# ATSAML21J18BU register map
Vendor: Microchip Technology Inc.; Series: SAML21; File version: B
CPU: CM0+ r0p1, little endian, no MPU, no FPU, VTOR, 2 interrupt priority bits, 29 interrupts
Registers are 32-bit, read-write, reset 0x0 unless marked. A register's access mark holds for its fields unless they carry their own. Offsets are from the block's base; [hi:lo] are bit positions; {n}, {i} and the like mark numbered series; 'fields as' and 'values as' point back to an identical list.

## MTB — Cortex-M0+ Micro-Trace Buffer
Base 0x41006000; register names take the prefix MTB_
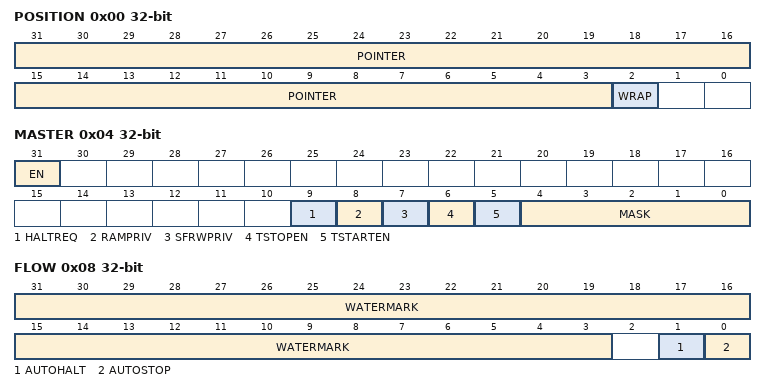
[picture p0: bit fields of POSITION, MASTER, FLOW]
0x00 POSITION — MTB Position
  [31:3] POINTER — Trace Packet Location Pointer
  [2] WRAP — Pointer Value Wraps
0x04 MASTER — MTB Master
  [31] EN — Main Trace Enable
  [9] HALTREQ — Halt Request
  [8] RAMPRIV — SRAM Privilege
  [7] SFRWPRIV — Special Function Register Write Privilege
  [6] TSTOPEN — Trace Stop Input Enable
  [5] TSTARTEN — Trace Start Input Enable
  [4:0] MASK — Maximum Value of the Trace Buffer in SRAM
0x08 FLOW — MTB Flow
  [31:3] WATERMARK — Watermark value
  [1] AUTOHALT — Auto Halt Request
  [0] AUTOSTOP — Auto Stop Tracing
0x0C BASE ro — MTB Base
0xF00 ITCTRL — MTB Integration Mode Control
0xFA0 CLAIMSET — MTB Claim Set
0xFA4 CLAIMCLR — MTB Claim Clear
0xFB0 LOCKACCESS — MTB Lock Access
0xFB4 LOCKSTATUS ro — MTB Lock Status
0xFB8 AUTHSTATUS ro — MTB Authentication Status
0xFBC DEVARCH ro — MTB Device Architecture
0xFC8 DEVID ro — MTB Device Configuration
0xFCC DEVTYPE ro — MTB Device Type
{0xFC0+4i} PID{i} ro (i=4..7) — Peripheral Identification {i}
{0xFE0+4i} PID{i} ro (i=0..3) — Peripheral Identification {i}
{0xFF0+4i} CID{i} ro (i=0..3) — Component Identification {i}

## OPAMP — Operational Amplifier
Base 0x43001800; register names take the prefix OPAMP_
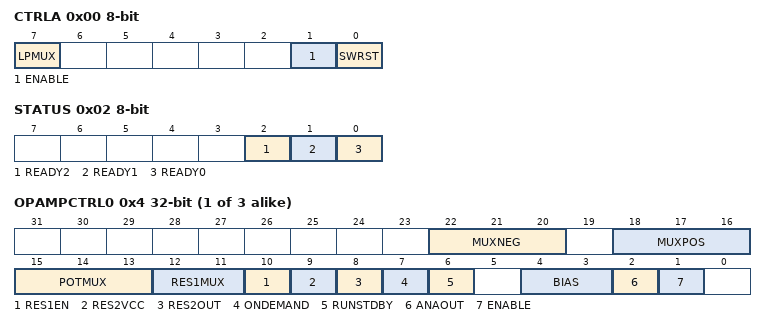
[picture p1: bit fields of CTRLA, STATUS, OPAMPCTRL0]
0x00 CTRLA 8-bit — Control A
  [7] LPMUX — Low-Power Mux
  [1] ENABLE
  [0] SWRST — Software Reset
0x02 STATUS 8-bit ro
  [2] READY2 — OPAMP 2 Ready
  [1] READY1 — OPAMP 1 Ready
  [0] READY0 — OPAMP 0 Ready
{0x4+4i} OPAMPCTRL{i} (i=0..2) — OPAMP n Control
  [22:20] MUXNEG — Negative Input Mux Selection
  [18:16] MUXPOS — Positive Input Mux Selection
  [15:13] POTMUX — Potentiometer Selection
  [12:11] RES1MUX — Resistor 1 Mux
  [10] RES1EN — Resistor 1 Enable
  [9] RES2VCC — Resistor ladder To VCC
  [8] RES2OUT — Resistor ladder To Output
  [7] ONDEMAND — On Demand Control
  [6] RUNSTDBY — Run in Standby
  [4:3] BIAS — Bias Selection
  [2] ANAOUT — Analog Output
  [1] ENABLE — Operational Amplifier Enable

## OSC32KCTRL — 32k Oscillators Control
Base 0x40001000; register names take the prefix OSC32KCTRL_
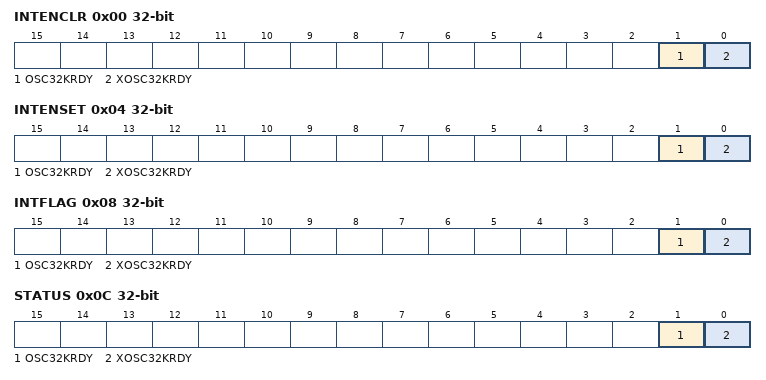
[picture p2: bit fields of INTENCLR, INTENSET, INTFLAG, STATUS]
0x00 INTENCLR — Interrupt Enable Clear
  [1] OSC32KRDY — OSC32K Ready Interrupt Enable
  [0] XOSC32KRDY — XOSC32K Ready Interrupt Enable
0x04 INTENSET — Interrupt Enable Set
  fields as INTENCLR
0x08 INTFLAG — Interrupt Flag Status and Clear
  [1] OSC32KRDY — OSC32K Ready
  [0] XOSC32KRDY — XOSC32K Ready
0x0C STATUS ro — Power and Clocks Status
  [1] OSC32KRDY — OSC32K Ready
  [0] XOSC32KRDY — XOSC32K Ready
0x10 RTCCTRL — Clock selection
  [2:0] RTCSEL — RTC Clock Selection
    0=ULP1K (1.024kHz from 32kHz internal ULP oscillator); 1=ULP32K (32.768kHz from 32kHz internal ULP oscillator); 2=OSC1K (1.024kHz from 32.768kHz internal oscillator); 3=OSC32K (32.768kHz from 32.768kHz internal oscillator); 4=XOSC1K (1.024kHz from 32.768kHz internal oscillator); 5=XOSC32K (32.768kHz from 32.768kHz external crystal oscillator)
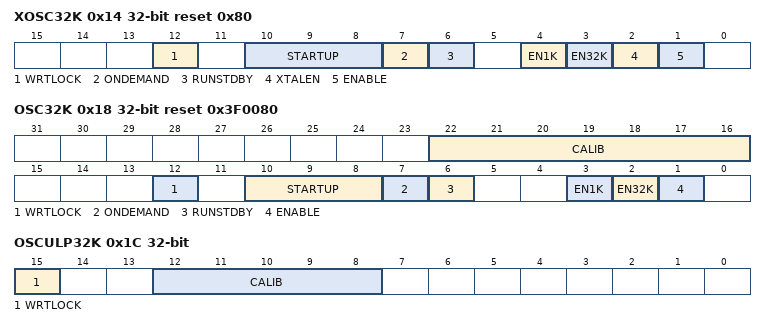
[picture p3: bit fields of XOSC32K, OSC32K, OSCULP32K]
0x14 XOSC32K reset 0x80 — 32kHz External Crystal Oscillator (XOSC32K) Control
  [12] WRTLOCK — Write Lock
  [10:8] STARTUP — Oscillator Start-Up Time
  [7] ONDEMAND — On Demand Control
  [6] RUNSTDBY — Run in Standby
  [4] EN1K — 1kHz Output Enable
  [3] EN32K — 32kHz Output Enable
  [2] XTALEN — Crystal Oscillator Enable
  [1] ENABLE — Oscillator Enable
0x18 OSC32K reset 0x3F0080 — 32kHz Internal Oscillator (OSC32K) Control
  [22:16] CALIB — Oscillator Calibration
  [12] WRTLOCK — Write Lock
  [10:8] STARTUP — Oscillator Start-Up Time
  [7] ONDEMAND — On Demand Control
  [6] RUNSTDBY — Run in Standby
  [3] EN1K — 1kHz Output Enable
  [2] EN32K — 32kHz Output Enable
  [1] ENABLE — Oscillator Enable
0x1C OSCULP32K — 32kHz Ultra Low Power Internal Oscillator (OSCULP32K) Control
  [15] WRTLOCK — Write Lock
  [12:8] CALIB — Oscillator Calibration

## Notices in the file
Copyright (c) 2018 Microchip Technology Inc.
SPDX-License-Identifier: Apache-2.0
Licensed under the Apache License, Version 2.0 (the "License");
you may not use this file except in compliance with the License.
You may obtain a copy of the License at
http://www.apache.org/licenses/LICENSE-2.0
Unless required by applicable law or agreed to in writing, software
distributed under the License is distributed on an "AS IS" BASIS,
WITHOUT WARRANTIES OR CONDITIONS OF ANY KIND, either express or implied.
See the License for the specific language governing permissions and
limitations under the License.
